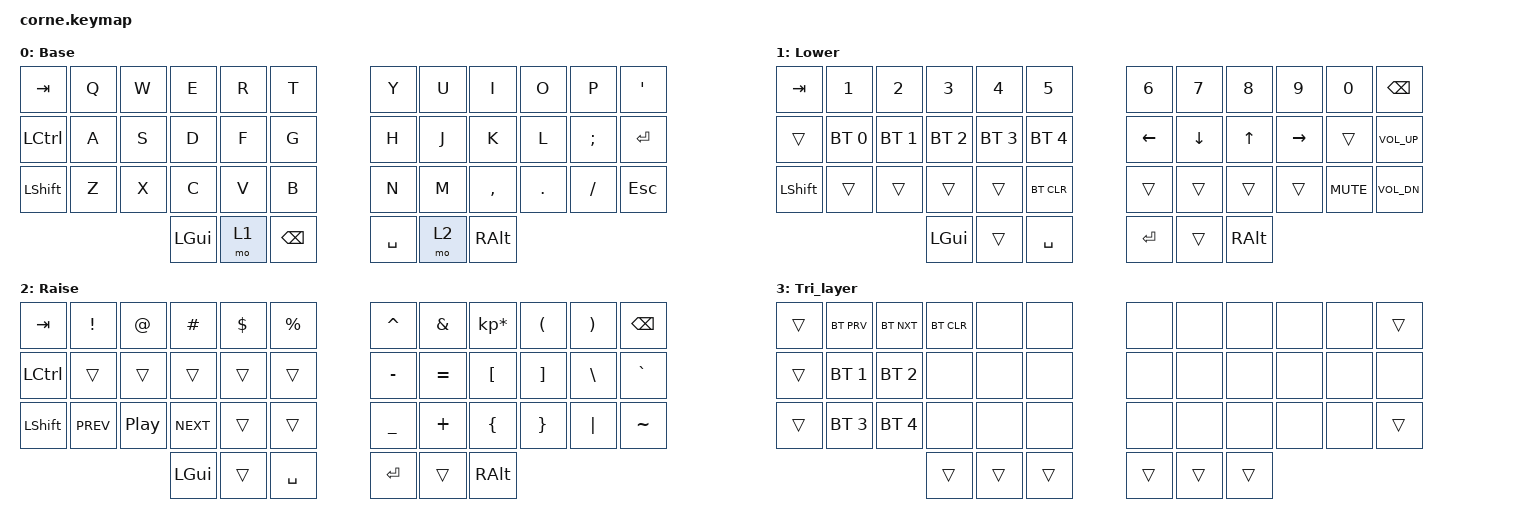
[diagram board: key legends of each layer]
// https://zmk.dev/docs/keymaps/list-of-keycodes

#include <behaviors.dtsi>
#include <dt-bindings/zmk/keys.h>
#include <dt-bindings/zmk/bt.h>

#define Base 0
#define Lower 1
#define Raise 2

  /{

  conditional_layers {
      compatible = "zmk,conditional-layers";
      tri_layer {
          if-layers = <1 2>;
          then-layer = <3>;
      };
  };
 
        keymap {
                compatible = "zmk,keymap";

                default_layer {
                        display-name = "Base";
                        bindings = <
   &kp TAB   &kp Q &kp W &kp E &kp R &kp T   &kp Y &kp U  &kp I     &kp O   &kp P    &kp SQT 
   &kp LCTRL &kp A &kp S &kp D &kp F &kp G   &kp H &kp J  &kp K     &kp L   &kp SEMI &kp RET
   &kp LSHFT &kp Z &kp X &kp C &kp V &kp B   &kp N &kp M  &kp COMMA &kp DOT &kp FSLH &kp ESC
                  &kp LGUI &mo 1 &kp BSPC&kp SPACE &mo 2 &kp RALT
                        >;
                };
                lower_layer {
                        display-name = "Lower";
                        bindings = <
   &kp TAB    &kp N1       &kp N2       &kp N3       &kp N4       &kp N5         &kp N6   &kp N7   &kp N8 &kp N9    &kp N0 &kp BSPC
   &trans &bt BT_SEL 0 &bt BT_SEL 1 &bt BT_SEL 2 &bt BT_SEL 3 &bt BT_SEL 4   &kp LEFT &kp DOWN &kp UP &kp RIGHT &trans &kp C_VOL_UP
   &kp LSHFT  &trans       &trans       &trans       &trans       &bt BT_CLR         &trans   &trans   &trans &trans  &kp C_MUTE  &kp C_VOL_DN
               	&kp LGUI     &trans       &kp SPACE      &kp RET  &trans   &kp RALT
                        >;
                };

                raise_layer {
                        display-name = "Raise";
                        bindings = <
   &kp  TAB  &kp EXCL &kp AT &kp HASH &kp DLLR &kp PRCNT   &kp CARET &kp AMPS  &kp KP_MULTIPLY &kp LPAR &kp RPAR &kp BSPC
   &kp LCTRL &trans   &trans &trans   &trans   &trans      &kp MINUS &kp EQUAL &kp LBKT        &kp RBKT &kp BSLH &kp GRAVE
   &kp LSHFT &kp C_PREV   &kp C_PP &kp C_NEXT   &trans   &trans      &kp UNDER &kp PLUS  &kp LBRC        &kp RBRC &kp PIPE &kp TILDE
                    	     &kp LGUI &trans   &kp SPACE   &kp RET   &trans    &kp RALT
                        >;
                };


 
    Tri_layer {
      bindings = <
        &trans           &bt BT_PRV   &bt BT_NXT   &bt BT_CLR       &none              &none                &none                 &none             &none             &none        &none         &trans 
        &trans           &bt BT_SEL 1 &bt BT_SEL 2 &none            &none              &none                &none                 &none             &none             &none        &none         &none 
        &trans           &bt BT_SEL 3 &bt BT_SEL 4 &none            &none              &none                &none                 &none             &none             &none        &none         &trans 
                                                   &trans           &trans             &trans               &trans                &trans            &trans 
      >;
    };   
                extra_1 {
                        status = "reserved";
                };

                extra_2 {
                        status = "reserved";
                };

                extra_3 {
                        status = "reserved";
                };
        };
};
